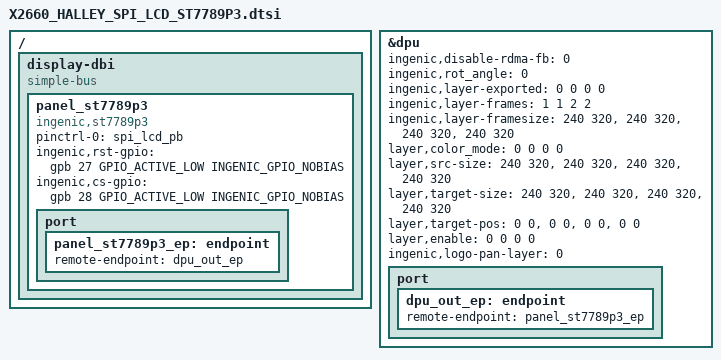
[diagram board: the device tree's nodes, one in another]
/ {

	display-dbi {
		compatible = "simple-bus";
		#interrupt-cells = <1>;
		#address-cells = <1>;
		#size-cells = <1>;
		ranges = <>;
		panel_st7789p3 {
			compatible = "ingenic,st7789p3";
			status = "okay";
			pinctrl-names = "default";
			pinctrl-0 = <&spi_lcd_pb>;
			ingenic,rst-gpio = <&gpb 27 GPIO_ACTIVE_LOW INGENIC_GPIO_NOBIAS>;
			ingenic,cs-gpio = <&gpb 28 GPIO_ACTIVE_LOW INGENIC_GPIO_NOBIAS>;
			port {
				panel_st7789p3_ep: endpoint {
					   remote-endpoint = <&dpu_out_ep>;
			   };
			};
		};
	};


};

&dpu {
	status = "okay";
    	ingenic,disable-rdma-fb = <0>;
    	ingenic,rot_angle = <0>;
    	/*Defines the init state of composer fb export infomations.*/
    	ingenic,layer-exported = <0 0 0 0>;
    	ingenic,layer-frames   = <1 1 2 2>;
    	ingenic,layer-framesize = <240 320>, <240 320>, <240 320>, <240 320>;   /*Max framesize for each layer.*/
    	layer,color_mode        = <0 0 0 0>;                                    /*src fmt,*/
    	layer,src-size          = <240 320>, <240 320>, <240 320>, <240 320>; /*Layer src size should smaller than framesize*/
    	layer,target-size       = <240 320>, <240 320>, <240 320>, <240 320>;  /*Target Size should smaller than src_size.*/
    	layer,target-pos        = <0 0>, <0 0>, <0 0>, <0 0>; /*target pos , the start point of the target panel.*/
    	layer,enable            = <0 0 0 0>;                                    /*layer enabled or disabled.*/
    	ingenic,logo-pan-layer  = <0>;                                          /*on which layer should init logo pan on.*/
	port {
		dpu_out_ep: endpoint {
		remote-endpoint = <&panel_st7789p3_ep>;
	    };
	};
};
